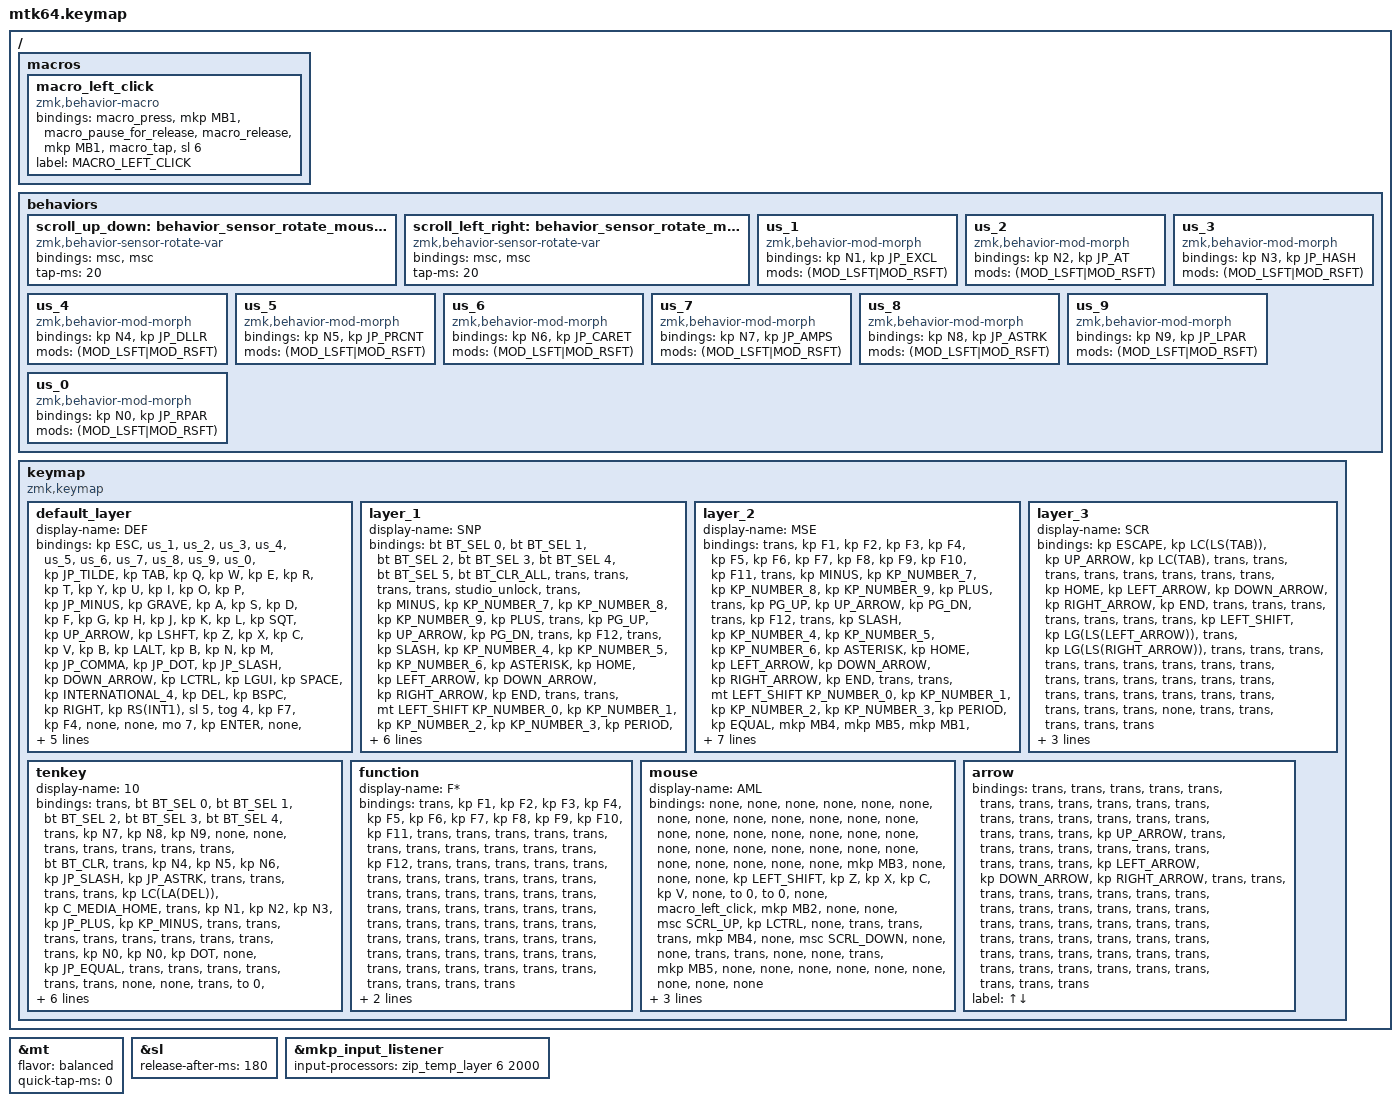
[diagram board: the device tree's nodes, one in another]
#include <input/processors.dtsi>
#include <behaviors.dtsi>
#include <dt-bindings/zmk/bt.h>
#include <dt-bindings/zmk/keys.h>
#include <dt-bindings/zmk/pointing.h>
#include "keycode_japanese.h"

// スクロール量の設定

#undef ZMK_POINTING_DEFAULT_SCRL_VAL

#define ZMK_POINTING_DEFAULT_SCRL_VAL 100

&mt {
    flavor = "balanced";
    quick-tap-ms = <0>;
};

&sl { release-after-ms = <180>; };

&mkp_input_listener { input-processors = <&zip_temp_layer 6 2000>; };

/ {
    macros {
        macro_left_click: macro_left_click {
            compatible = "zmk,behavior-macro";
            #binding-cells = <0>;
            bindings =
                <&macro_press>,
                <&mkp MB1>,
                <&macro_pause_for_release>,
                <&macro_release>,
                <&mkp MB1>,
                <&macro_tap>,
                <&sl 6>;

            label = "MACRO_LEFT_CLICK";
        };
    };

    behaviors {
        // 垂直スクロール用のbehaviorの設定

        scroll_up_down: behavior_sensor_rotate_mouse_wheel_up_down {
            compatible = "zmk,behavior-sensor-rotate-var";
            #sensor-binding-cells = <2>;
            bindings = <&msc>, <&msc>;

            tap-ms = <20>;
        };

        // 水平スクロール用のbehaviorの設定

        scroll_left_right: behavior_sensor_rotate_mouse_wheel_left_right {
            compatible = "zmk,behavior-sensor-rotate-var";
            #sensor-binding-cells = <2>;
            bindings = <&msc>, <&msc>;

            tap-ms = <20>;
        };

        us_1: us_1 {
            compatible = "zmk,behavior-mod-morph";
            #binding-cells = <0>;
            bindings = <&kp N1>, <&kp JP_EXCL>;

            mods = <(MOD_LSFT|MOD_RSFT)>;
        };

        us_2: us_2 {
            compatible = "zmk,behavior-mod-morph";
            #binding-cells = <0>;
            bindings = <&kp N2>, <&kp JP_AT>;

            mods = <(MOD_LSFT|MOD_RSFT)>;
        };

        us_3: us_3 {
            compatible = "zmk,behavior-mod-morph";
            #binding-cells = <0>;
            bindings = <&kp N3>, <&kp JP_HASH>;

            mods = <(MOD_LSFT|MOD_RSFT)>;
        };

        us_4: us_4 {
            compatible = "zmk,behavior-mod-morph";
            #binding-cells = <0>;
            bindings = <&kp N4>, <&kp JP_DLLR>;

            mods = <(MOD_LSFT|MOD_RSFT)>;
        };

        us_5: us_5 {
            compatible = "zmk,behavior-mod-morph";
            #binding-cells = <0>;
            bindings = <&kp N5>, <&kp JP_PRCNT>;

            mods = <(MOD_LSFT|MOD_RSFT)>;
        };

        us_6: us_6 {
            compatible = "zmk,behavior-mod-morph";
            #binding-cells = <0>;
            bindings = <&kp N6>, <&kp JP_CARET>;

            mods = <(MOD_LSFT|MOD_RSFT)>;
        };

        us_7: us_7 {
            compatible = "zmk,behavior-mod-morph";
            #binding-cells = <0>;
            bindings = <&kp N7>, <&kp JP_AMPS>;

            mods = <(MOD_LSFT|MOD_RSFT)>;
        };

        us_8: us_8 {
            compatible = "zmk,behavior-mod-morph";
            #binding-cells = <0>;
            bindings = <&kp N8>, <&kp JP_ASTRK>;

            mods = <(MOD_LSFT|MOD_RSFT)>;
        };

        us_9: us_9 {
            compatible = "zmk,behavior-mod-morph";
            #binding-cells = <0>;
            bindings = <&kp N9>, <&kp JP_LPAR>;

            mods = <(MOD_LSFT|MOD_RSFT)>;
        };

        us_0: us_0 {
            compatible = "zmk,behavior-mod-morph";
            #binding-cells = <0>;
            bindings = <&kp N0>, <&kp JP_RPAR>;

            mods = <(MOD_LSFT|MOD_RSFT)>;
        };
    };

    keymap {
        compatible = "zmk,keymap";

        default_layer {
            display-name = "DEF";
            bindings = <
&kp ESC  &us_1  &us_2  &us_3  &us_4  &us_5  &us_6  &us_7  &us_8  &us_9  &us_0  &kp JP_TILDE  &kp TAB  &kp Q  &kp W  &kp E  &kp R  &kp T  &kp Y  &kp U  &kp I  &kp O  &kp P  &kp JP_MINUS  &kp GRAVE  &kp A  &kp S  &kp D  &kp F  &kp G  &kp H  &kp J  &kp K  &kp L  &kp SQT  &kp UP_ARROW  &kp LSHFT  &kp Z  &kp X  &kp C  &kp V  &kp B  &kp LALT  &kp B  &kp N  &kp M  &kp JP_COMMA  &kp JP_DOT  &kp JP_SLASH  &kp DOWN_ARROW  &kp LCTRL  &kp LGUI  &kp SPACE  &kp INTERNATIONAL_4  &kp DEL  &kp BSPC  &kp RIGHT  &kp RS(INT1)  &sl 5  &tog 4  &kp F7  &kp F4  &none  &none  &mo 7  &kp ENTER  &none  &none  &none  &none  &none  &none  &none  &none  &none
            >;

            sensor-bindings =
                <&scroll_left_right SCRL_LEFT SCRL_RIGHT>,
                <&scroll_up_down SCRL_UP SCRL_DOWN>;
        };

        layer_1 {
            display-name = "SNP";
            bindings = <
&bt BT_SEL 0  &bt BT_SEL 1  &bt BT_SEL 2  &bt BT_SEL 3  &bt BT_SEL 4  &bt BT_SEL 5  &bt BT_CLR_ALL  &trans  &trans  &trans  &trans  &studio_unlock  &trans  &kp MINUS  &kp KP_NUMBER_7  &kp KP_NUMBER_8  &kp KP_NUMBER_9  &kp PLUS  &trans  &kp PG_UP  &kp UP_ARROW  &kp PG_DN  &trans  &kp F12  &trans  &kp SLASH  &kp KP_NUMBER_4  &kp KP_NUMBER_5  &kp KP_NUMBER_6  &kp ASTERISK  &kp HOME  &kp LEFT_ARROW  &kp DOWN_ARROW  &kp RIGHT_ARROW  &kp END  &trans  &trans  &mt LEFT_SHIFT KP_NUMBER_0  &kp KP_NUMBER_1  &kp KP_NUMBER_2  &kp KP_NUMBER_3  &kp PERIOD  &kp EQUAL  &mkp MB4  &mkp MB5  &mkp MB1  &mkp MB2  &mkp MB3  &trans  &trans  &trans  &trans  &trans  &trans  &trans  &trans  &trans  &trans  &trans  &trans  &trans  &trans  &trans  &trans  &trans  &trans  &trans  &trans  &trans  &trans  &trans  &trans  &trans  &trans  &trans
            >;
        };

        layer_2 {
            display-name = "MSE";
            bindings = <
&trans  &kp F1  &kp F2  &kp F3  &kp F4  &kp F5  &kp F6  &kp F7  &kp F8  &kp F9  &kp F10  &kp F11  &trans  &kp MINUS  &kp KP_NUMBER_7  &kp KP_NUMBER_8  &kp KP_NUMBER_9  &kp PLUS  &trans  &kp PG_UP  &kp UP_ARROW  &kp PG_DN  &trans  &kp F12  &trans  &kp SLASH  &kp KP_NUMBER_4  &kp KP_NUMBER_5  &kp KP_NUMBER_6  &kp ASTERISK  &kp HOME  &kp LEFT_ARROW  &kp DOWN_ARROW  &kp RIGHT_ARROW  &kp END  &trans  &trans  &mt LEFT_SHIFT KP_NUMBER_0  &kp KP_NUMBER_1  &kp KP_NUMBER_2  &kp KP_NUMBER_3  &kp PERIOD  &kp EQUAL  &mkp MB4  &mkp MB5  &mkp MB1  &mkp MB2  &mkp MB3  &trans  &trans  &trans  &trans  &trans  &trans  &trans  &trans  &trans  &trans  &trans  &trans  &trans  &trans  &trans  &trans  &trans  &trans  &trans  &trans  &trans  &trans  &trans  &trans  &trans  &trans  &trans
            >;

            sensor-bindings = <
                &inc_dec_kp TAB LS(TAB)
                &inc_dec_kp PG_UP PG_DN
            >;
        };

        layer_3 {
            display-name = "SCR";
            bindings = <
&kp ESCAPE  &kp LC(LS(TAB))  &kp UP_ARROW  &kp LC(TAB)  &trans  &trans  &trans  &trans  &trans  &trans  &trans  &trans  &kp HOME  &kp LEFT_ARROW  &kp DOWN_ARROW  &kp RIGHT_ARROW  &kp END  &trans  &trans  &trans  &trans  &trans  &trans  &trans  &kp LEFT_SHIFT  &kp LG(LS(LEFT_ARROW))  &trans  &kp LG(LS(RIGHT_ARROW))  &trans  &trans  &trans  &trans  &trans  &trans  &trans  &trans  &trans  &trans  &trans  &trans  &trans  &trans  &trans  &trans  &trans  &trans  &trans  &trans  &trans  &trans  &trans  &trans  &none  &trans  &trans  &trans  &trans  &trans
            >;

            sensor-bindings = <
                &scroll_left_right SCRL_LEFT SCRL_RIGHT
                &scroll_up_down SCRL_UP SCRL_DOWN
            >;
        };

        tenkey {
            display-name = "10";
            bindings = <
&trans  &bt BT_SEL 0  &bt BT_SEL 1  &bt BT_SEL 2  &bt BT_SEL 3  &bt BT_SEL 4  &trans  &kp N7  &kp N8  &kp N9  &none  &none  &trans  &trans  &trans  &trans  &trans  &bt BT_CLR  &trans  &kp N4  &kp N5  &kp N6  &kp JP_SLASH  &kp JP_ASTRK  &trans  &trans  &trans  &trans  &kp LC(LA(DEL))  &kp C_MEDIA_HOME  &trans  &kp N1  &kp N2  &kp N3  &kp JP_PLUS  &kp KP_MINUS  &trans  &trans  &trans  &trans  &trans  &trans  &trans  &trans  &trans  &kp N0  &kp N0  &kp DOT  &none  &kp JP_EQUAL  &trans  &trans  &trans  &trans  &trans  &trans  &none  &none  &trans  &to 0  &trans  &trans  &trans  &trans  &mo 7  &trans  &trans  &trans  &trans  &trans  &trans  &trans  &trans  &trans
            >;

            sensor-bindings =
                <&scroll_left_right SCRL_LEFT SCRL_RIGHT>,
                <&scroll_up_down SCRL_UP SCRL_DOWN>;
        };

        function {
            display-name = "F*";
            bindings = <
&trans  &kp F1  &kp F2  &kp F3  &kp F4  &kp F5  &kp F6  &kp F7  &kp F8  &kp F9  &kp F10  &kp F11  &trans  &trans  &trans  &trans  &trans  &trans  &trans  &trans  &trans  &trans  &trans  &kp F12  &trans  &trans  &trans  &trans  &trans  &trans  &trans  &trans  &trans  &trans  &trans  &trans  &trans  &trans  &trans  &trans  &trans  &trans  &trans  &trans  &trans  &trans  &trans  &trans  &trans  &trans  &trans  &trans  &trans  &trans  &trans  &trans  &trans  &trans  &trans  &trans  &trans  &trans  &trans  &trans  &trans  &trans  &trans  &trans  &trans  &trans  &trans  &trans  &trans  &trans  &trans
            >;

            sensor-bindings =
                <&inc_dec_kp C_VOL_UP C_VOL_DN>,
                <&scroll_up_down SCRL_UP SCRL_DOWN>;
        };

        mouse {
            display-name = "AML";
            bindings = <
&none  &none  &none  &none  &none  &none  &none  &none  &none  &none  &none  &none  &none  &none  &none  &none  &none  &none  &none  &none  &none  &none  &none  &none  &none  &none  &none  &none  &none  &none  &none  &none  &mkp MB3  &none  &none  &none  &kp LEFT_SHIFT  &kp Z  &kp X  &kp C  &kp V  &none  &to 0  &to 0  &none  &macro_left_click  &mkp MB2  &none  &none  &msc SCRL_UP  &kp LCTRL  &none  &trans  &trans  &trans  &mkp MB4  &none  &msc SCRL_DOWN  &none  &none  &trans  &trans  &none  &none  &trans  &mkp MB5  &none  &none  &none  &none  &none  &none  &none  &none  &none
            >;

            sensor-bindings =
                <&scroll_left_right SCRL_LEFT SCRL_RIGHT>,
                <&scroll_up_down SCRL_UP SCRL_DOWN>;
        };

        arrow {
            bindings = <
&trans  &trans  &trans  &trans  &trans  &trans  &trans  &trans  &trans  &trans  &trans  &trans  &trans  &trans  &trans  &trans  &trans  &trans  &trans  &trans  &kp UP_ARROW  &trans  &trans  &trans  &trans  &trans  &trans  &trans  &trans  &trans  &trans  &kp LEFT_ARROW  &kp DOWN_ARROW  &kp RIGHT_ARROW  &trans  &trans  &trans  &trans  &trans  &trans  &trans  &trans  &trans  &trans  &trans  &trans  &trans  &trans  &trans  &trans  &trans  &trans  &trans  &trans  &trans  &trans  &trans  &trans  &trans  &trans  &trans  &trans  &trans  &trans  &trans  &trans  &trans  &trans  &trans  &trans  &trans  &trans  &trans  &trans  &trans
            >;

            label = "↑↓";
        };
    };
};
